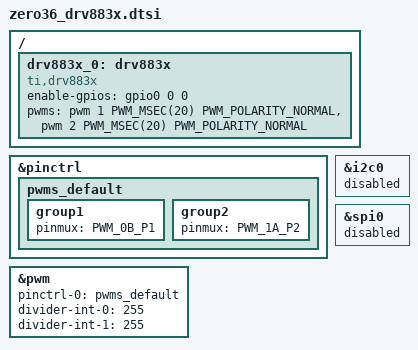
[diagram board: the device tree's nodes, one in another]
/*
 * Copyright (c) 2020 Pete Johanson
 *
 * SPDX-License-Identifier: MIT
 */

#include <dt-bindings/pinctrl/rpi-pico-rp2040-pinctrl.h>
#include <zephyr/dt-bindings/pwm/pwm.h>

&pinctrl {
    pwms_default: pwms_default {
        group1 {
            pinmux = <PWM_0B_P1>;
        };
        group2 {
            pinmux = <PWM_1A_P2>;
        };
        // group3 {
        //     pinmux = <PWM_1B_P3>;
        // };
        // group4 {
        //     pinmux = <PWM_2A_P4>;
        // };
    };
};

&i2c0 {
	status = "disabled";
};

&spi0 {
	status = "disabled";
};

&pwm {
    status = "okay";
    pinctrl-0 = <&pwms_default>;
    pinctrl-names = "default";
    divider-int-0 = <255>;
    divider-int-1 = <255>;
};

/ {
  drv883x_0: drv883x {
    compatible = "ti,drv883x";

    enable-gpios = <&gpio0 0 0 (GPIO_ACTIVE_HIGH | GPIO_PULL_DOWN)>;

    /* map PWM gpios to IN1 .. IN4 pin on drv883x */
    pwms = <&pwm 1 PWM_MSEC(20) PWM_POLARITY_NORMAL>
         , <&pwm 2 PWM_MSEC(20) PWM_POLARITY_NORMAL>
         //  , <&pwm 3 PWM_MSEC(20) PWM_POLARITY_NORMAL>
         //  , <&pwm 4 PWM_MSEC(20) PWM_POLARITY_NORMAL>
         ;

  };
};
